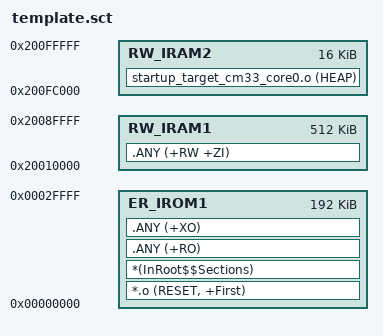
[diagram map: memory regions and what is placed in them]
; *************************************************************
; *** Scatter-Loading Description File generated by uVision ***
; *************************************************************

LR_IROM1 0x00000000 0x00030000  {    ; load region size_region
  ER_IROM1 0x00000000 0x00030000  {  ; load address = execution address
   *.o (RESET, +First)
   *(InRoot$$Sections)
   .ANY (+RO)
   .ANY (+XO)
  }
  RW_IRAM1 0x20010000 0x00080000  {  ; RW data
   .ANY (+RW +ZI)
  }
  RW_IRAM2 0x200FC000 0x00004000  {  ; RW data
    startup_target_cm33_core0.o  (HEAP)
  }
}

